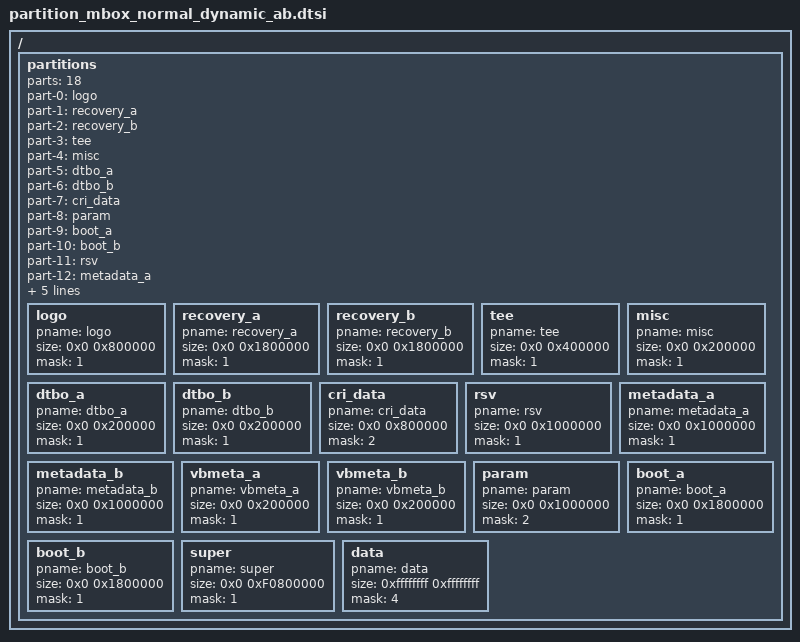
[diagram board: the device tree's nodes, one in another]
/*
 * Amlogic partition set for normal
 *
 * Copyright (c) 2017-2017 Amlogic Ltd
 *
 * This file is licensed under a dual GPLv2 or BSD license.
 *
 */

#include "firmware_avb_Q_ab.dtsi"

/ {
    partitions: partitions{
		parts = <18>;
		part-0 = <&logo>;
		part-1 = <&recovery_a>;
		part-2 = <&recovery_b>;
		part-3 = <&tee>;
		part-4 = <&misc>;
		part-5 = <&dtbo_a>;
		part-6 = <&dtbo_b>;
		part-7 = <&cri_data>;
		part-8 = <&param>;
		part-9 = <&boot_a>;
		part-10 = <&boot_b>;
		part-11 = <&rsv>;
		part-12 = <&metadata_a>;
		part-13 = <&metadata_b>;
		part-14 = <&vbmeta_a>;
		part-15 = <&vbmeta_b>;
		part-16 = <&super>;
		part-17 = <&data>;

		logo:logo{
			pname = "logo";
			size = <0x0 0x800000>;
			mask = <1>;
		};
		recovery_a:recovery_a{
			pname = "recovery_a";
			size = <0x0 0x1800000>;
			mask = <1>;
		};
		recovery_b:recovery_b{
			pname = "recovery_b";
			size = <0x0 0x1800000>;
			mask = <1>;
		};
		tee:tee{
			pname = "tee";
			size = <0x0 0x400000>;
			mask = <1>;
		};
		misc:misc{
			pname = "misc";
			size = <0x0 0x200000>;
			mask = <1>;
		};
		dtbo_a:dtbo_a{
			pname = "dtbo_a";
			size = <0x0 0x200000>;
			mask = <1>;
		};
		dtbo_b:dtbo_b{
			pname = "dtbo_b";
			size = <0x0 0x200000>;
			mask = <1>;
		};
		cri_data:cri_data
		{
			pname = "cri_data";
			size = <0x0 0x800000>;
			mask = <2>;
		};
		rsv:rsv{
			pname = "rsv";
			size = <0x0 0x1000000>;
			mask = <1>;
		};
		metadata_a:metadata_a{
			pname = "metadata_a";
			size = <0x0 0x1000000>;
			mask = <1>;
		};
		metadata_b:metadata_b{
			pname = "metadata_b";
			size = <0x0 0x1000000>;
			mask = <1>;
		};
		vbmeta_a:vbmeta_a{
			pname = "vbmeta_a";
			size = <0x0 0x200000>;
			mask = <1>;
		};
		vbmeta_b:vbmeta_b{
			pname = "vbmeta_b";
			size = <0x0 0x200000>;
			mask = <1>;
		};
		param:param{
			pname = "param";
			size = <0x0 0x1000000>;
			mask = <2>;
		};
		boot_a:boot_a
		{
			pname = "boot_a";
			size = <0x0 0x1800000>;
			mask = <1>;
		};
		boot_b:boot_b
		{
			pname = "boot_b";
			size = <0x0 0x1800000>;
			mask = <1>;
		};
		super:super
		{
			pname = "super";
			size = <0x0 0xF0800000>;
			mask = <1>;
		};
		data:data
		{
			pname = "data";
			size = <0xffffffff 0xffffffff>;
			mask = <4>;
		};
	};
};/* end of / */
